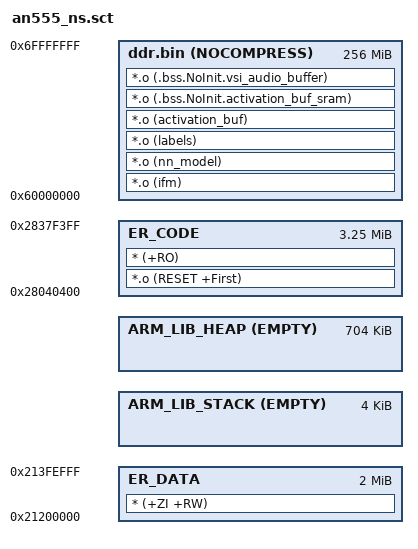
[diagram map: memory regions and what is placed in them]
#! armclang --target=arm-arm-none-eabi -march=armv8.1-m.main+mve.fp+fp.dp -E -x c
/*
 * Copyright (c) 2021-2023 Arm Limited. All rights reserved.
 *
 * Licensed under the Apache License, Version 2.0 (the "License");
 * you may not use this file except in compliance with the License.
 * You may obtain a copy of the License at
 *
 *     http://www.apache.org/licenses/LICENSE-2.0
 *
 * Unless required by applicable law or agreed to in writing, software
 * distributed under the License is distributed on an "AS IS" BASIS,
 * WITHOUT WARRANTIES OR CONDITIONS OF ANY KIND, either express or implied.
 * See the License for the specific language governing permissions and
 * limitations under the License.
 */

#define FLASH_NS_PARTITION_SIZE 0x340000
#define FLASH_S_PARTITION_SIZE  0x40000
#define ROM_START               0x28000000
#define BL2_HEADER_SIZE         0x400
#define BL2_TRAILER_SIZE        0xC00
#define ISRAM0_BASE_ADDRESS     0x21000000
#define ISRAM1_OFFSET           0x00200000
#define ISRAM1_SIZE             0x00200000
#define PROVISIONING_SIZE       0x1000
#define STACK_SIZE              0x00001000
#define HEAP_SIZE               0x000B0000

LR_CODE (ROM_START + ((((0) + (FLASH_S_PARTITION_SIZE)) + BL2_HEADER_SIZE))) {
    ER_CODE (ROM_START + ((((0) + (FLASH_S_PARTITION_SIZE)) + BL2_HEADER_SIZE))) (((FLASH_NS_PARTITION_SIZE) - BL2_HEADER_SIZE - BL2_TRAILER_SIZE)) {
        *.o (RESET +First)
        * (+RO)
    }

    ; The last 0x1000 bytes are reserved for the provisioning bundle
    ER_DATA (ISRAM0_BASE_ADDRESS + ((ISRAM1_OFFSET))) (ISRAM1_SIZE - PROVISIONING_SIZE) {
        * (+ZI +RW)
    }


    ARM_LIB_STACK +0 ALIGN 32 EMPTY (STACK_SIZE) {
    }

    ARM_LIB_HEAP +0 ALIGN 8 EMPTY (HEAP_SIZE) {
    }

    ;-----------------------------------------------------
    ; SSE-300's internal SRAM of 4MiB - reserved for
    ; activation buffers.
    ; This region should have 3 cycle read latency from
    ; both Cortex-M55 and Ethos-U55
    ;-----------------------------------------------------
    ddr.bin       0x60000000  NOCOMPRESS ALIGN 16 0x10000000
    {
        ; nn model's baked in input matrices
        *.o (ifm)

        ; nn model
        *.o (nn_model)

        ; labels
        *.o (labels)

        ; if the activation buffer (tensor arena) doesn't
        ; fit in the SRAM region, we accommodate it here
        *.o (activation_buf)

        ; activation buffers a.k.a tensor arena when memory mode dedicated sram
        *.o (.bss.NoInit.activation_buf_sram)

        ; Buffer for transferring VSI audio data from S to NS
        *.o (.bss.NoInit.vsi_audio_buffer)
    }
}
